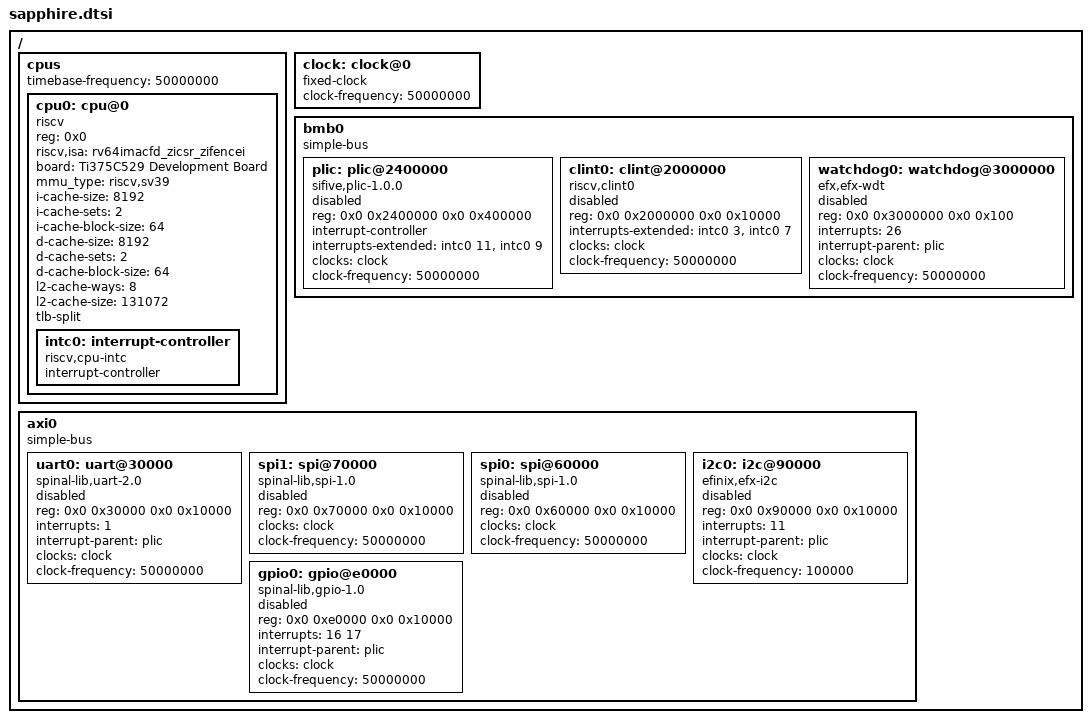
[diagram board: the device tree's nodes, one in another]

/dts-v1/;

/ {
	#address-cells = <2>;
	#size-cells = <2>;
	
	cpus {
		#address-cells = <1>;
		#size-cells = <0>;
		timebase-frequency = <50000000>;
		
		cpu0: cpu@0 {
			reg = <0x0>;
			compatible = "riscv";
			device_type = "cpu";
			riscv,isa = "rv64imacfd_zicsr_zifencei";
			board = "Ti375C529 Development Board";
			mmu_type = "riscv,sv39";
			i-cache-size = <8192>;
			i-cache-sets = <2>;
			i-cache-block-size = <64>;
			d-cache-size = <8192>;
			d-cache-sets = <2>;
			d-cache-block-size = <64>;
			l2-cache-ways = <8>;
			l2-cache-size = <131072>;
			tlb-split;
			status = "okay";
			
			intc0: interrupt-controller {
				#interrupt-cells = <1>;
				interrupt-controller;
				compatible = "riscv,cpu-intc";
			};
		};
		
	};
	

        clock: clock@0 {
        	compatible = "fixed-clock";
         	device_type = "clock";
        	clock-frequency = <50000000>;
        	#clock-cells = <0>;
        	status = "okay";
        };


        bmb0 {
                #address-cells = <2>;
                #size-cells = <2>;
                compatible = "simple-bus";
		ranges = <0x0 0x0 0x0 0x0 0x0 0x4000000>;

                plic: plic@2400000 {
                        #interrupt-cells = <1>;
                        reg = <0x0 0x2400000 0x0 0x400000>;
                        compatible = "sifive,plic-1.0.0", "sifive,fu540-c000-plic";
                        interrupt-controller;
                        interrupts-extended = <&intc0  11 &intc0  9>;
                        clocks = <&clock>;
                        clock-frequency = <50000000>;
                        status = "disabled";
                };

                clint0: clint@2000000 {
                        reg = <0x0 0x2000000 0x0 0x10000>;
                        compatible = "riscv,clint0";
                        interrupts-extended = <&intc0  3 &intc0  7>;
                        clocks = <&clock>;
                        clock-frequency = <50000000>;
                        status = "disabled";
                };

		watchdog0: watchdog@3000000 {
                        reg = <0x0 0x3000000 0x0 0x100>;
                        compatible = "efx,efx-wdt";
                        interrupts = <26>;
                        interrupt-parent = <&plic>;
                        clocks = <&clock>;
                        clock-frequency = <50000000>;
                        status = "disabled";
                };

        };

        axi0 {
                #address-cells = <2>;
                #size-cells = <2>;
                compatible = "simple-bus";
                //ranges = <0x0 0x0 0x0 0x8000000 0x0 0x1000000>;
		ranges = <0x0 0x0 0x0 0x08000000 0x0 0x2400000>;

                uart0: uart@30000 {
                        reg = <0x0 0x30000 0x0 0x10000>;
                        compatible = "spinal-lib,uart-2.0";
                        interrupts = <1>;
                        interrupt-parent = <&plic>;
                        clocks = <&clock>;
                        clock-frequency = <50000000>;
                        status = "disabled";
                };

                spi1: spi@70000 {
                        reg = <0x0 0x70000 0x0 0x10000>;
                        compatible = "spinal-lib,spi-1.0";
                        clocks = <&clock>;
                        clock-frequency = <50000000>;
                        status = "disabled";
                };

		spi0: spi@60000 {
                        reg = <0x0 0x60000 0x0 0x10000>;
                        compatible = "spinal-lib,spi-1.0";
                        clocks = <&clock>;
                        clock-frequency = <50000000>;
                        status = "disabled";
                };

		i2c0: i2c@90000 {
			reg = <0x0 0x90000 0x0 0x10000>;
			compatible = "efinix,efx-i2c";
			interrupts = <11>;
                        interrupt-parent = <&plic>;
                        clocks = <&clock>;
                        clock-frequency = <100000>;
			status = "disabled";
		};

		gpio0: gpio@e0000 {
                        #interrupt-cells = <2>;
			reg = <0x0 0xe0000 0x0 0x10000>;
                        compatible = "spinal-lib,gpio-1.0";
                        interrupts = <16 17>;
                        interrupt-parent = <&plic>;
                        clocks = <&clock>;
                        clock-frequency = <50000000>;
                        status = "disabled";
                };
	};
};
